# AT32M416xx_v2 register map
Vendor: Keil; Series: AT32M416; File version: 1.0
CPU: CM4 r0p1, little endian, no MPU, FPU, 4 interrupt priority bits
Registers are 32-bit, read-write, reset 0x0 unless marked. A register's access mark holds for its fields unless they carry their own. Offsets are from the block's base; [hi:lo] are bit positions; {n}, {i} and the like mark numbered series.

## TMR3 — General purpose timer
Base 0x40000400
Same registers: TMR4 0x40000800
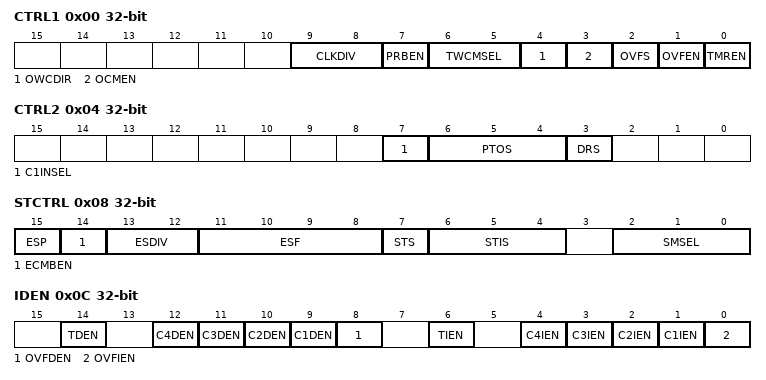
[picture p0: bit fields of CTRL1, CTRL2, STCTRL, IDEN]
0x00 CTRL1 — Control register 1
  [9:8] CLKDIV — Clock divider
  [7] PRBEN — Period buffer enable
  [6:5] TWCMSEL — Two-way count mode selection
  [4] OWCDIR — One-way count direction
  [3] OCMEN — One cycle mode enable
  [2] OVFS — Overflow event source
  [1] OVFEN — Overflow event enable
  [0] TMREN — TMR enable
0x04 CTRL2 — Control register 2
  [7] C1INSEL — C1IN selection
  [6:4] PTOS — Primary TMR output selection
  [3] DRS — DMA request source
0x08 STCTRL — Subordinate TMR control register
  [15] ESP — External signal polarity
  [14] ECMBEN — External clock mode B enable
  [13:12] ESDIV — External signal divider
  [11:8] ESF — External signal filter
  [7] STS — Subordinate TMR synchronization
  [6:4] STIS — Subordinate TMR input selection
  [2:0] SMSEL — Subordinate TMR mode selection
0x0C IDEN — Interrupt/DMA enable register
  [14] TDEN — Trigger DMA request enable
  [n+8] C{n}DEN (n=1..4) — Channel {n} DMA request enable
  [8] OVFDEN — Overflow DMA request enable
  [6] TIEN — Trigger interrupt enable
  [n] C{n}IEN (n=1..4) — Channel {n} interrupt enable
  [0] OVFIEN — Overflow interrupt enable
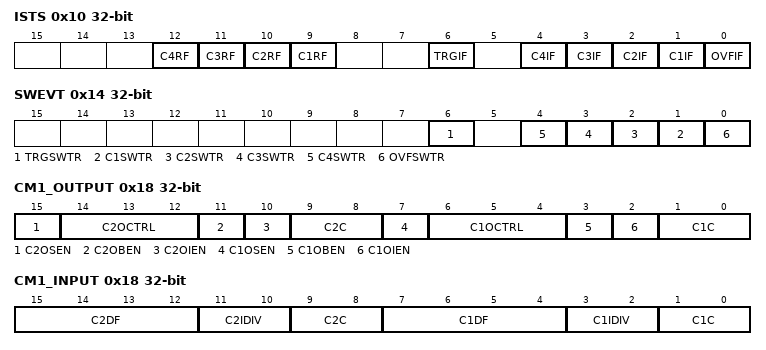
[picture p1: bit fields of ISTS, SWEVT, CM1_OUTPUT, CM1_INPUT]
0x10 ISTS — Interrupt status register
  [n+8] C{n}RF (n=1..4) — Channel {n} recapture flag
  [6] TRGIF — Trigger interrupt flag
  [n] C{n}IF (n=1..4) — Channel {n} interrupt flag
  [0] OVFIF — Overflow interrupt flag
0x14 SWEVT — Software event register
  [6] TRGSWTR — Trigger event triggered by software
  [n] C{n}SWTR (n=1..4) — Channel {n} event triggered by software
  [0] OVFSWTR — Overflow event triggered by software
0x18 CM1_OUTPUT — Channel output mode register
  [15] C2OSEN — Channel 2 output switch enable
  [14:12] C2OCTRL — Channel 2 output control
  [11] C2OBEN — Channel 2 output buffer enable
  [10] C2OIEN — Channel 2 output immediately enable
  [9:8] C2C — Channel 2 configure
  [7] C1OSEN — Channel 1 output switch enable
  [6:4] C1OCTRL — Channel 1 output control
  [3] C1OBEN — Channel 1 output buffer enable
  [2] C1OIEN — Channel 1 output immediately enable
  [1:0] C1C — Channel 1 configure
0x18 CM1_INPUT (alternate view of CM1_OUTPUT) — Channel input mode register 1
  [15:12] C2DF — Channel 2 digital filter
  [11:10] C2IDIV — Channel 2 input divider
  [9:8] C2C — Channel 2 configure
  [7:4] C1DF — Channel 1 digital filter
  [3:2] C1IDIV — Channel 1 input divider
  [1:0] C1C — Channel 1 configure
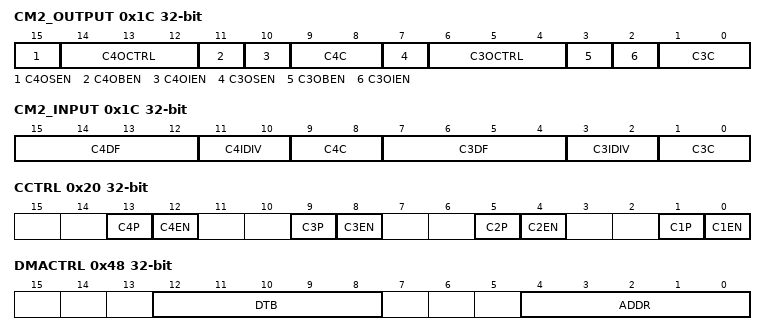
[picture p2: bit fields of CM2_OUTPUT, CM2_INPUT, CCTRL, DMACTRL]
0x1C CM2_OUTPUT — Channel output mode register 2
  [15] C4OSEN — Channel 4 output switch enable
  [14:12] C4OCTRL — Channel 4 output control
  [11] C4OBEN — Channel 4 output buffer enable
  [10] C4OIEN — Channel 4 output immediately enable
  [9:8] C4C — Channel 4 configure
  [7] C3OSEN — Channel 3 output switch enable
  [6:4] C3OCTRL — Channel 3 output control
  [3] C3OBEN — Channel 3 output buffer enable
  [2] C3OIEN — Channel 3 output immediately enable
  [1:0] C3C — Channel 3 configure
0x1C CM2_INPUT (alternate view of CM2_OUTPUT) — Channel input mode register 2
  [15:12] C4DF — Channel 4 digital filter
  [11:10] C4IDIV — Channel 4 input divider
  [9:8] C4C — Channel 4 configure
  [7:4] C3DF — Channel 3 digital filter
  [3:2] C3IDIV — Channel 3 input divider
  [1:0] C3C — Channel 3 configure
0x20 CCTRL — Channel control register
  [4n-3] C{n}P (n=1..4) — Channel {n} Polarity
  [4n-4] C{n}EN (n=1..4) — Channel {n} enable
0x24 CVAL — Counter value
  [15:0] CVAL
0x28 DIV — Divider value
  [15:0] DIV
0x2C PR — Period value
  [15:0] PR
{0x30+4i} C{i}DT (i=1..4) — Channel {i} data register
  [15:0] C{i}DT
0x48 DMACTRL — DMA control register
  [12:8] DTB — DMA transfer bytes
  [4:0] ADDR — DMA transfer address offset
0x4C DMADT — DMA data register
  [15:0] DMADT
0x50 OPT1 — option 1 register
  [0] CORAW_OFF — CORAW_OFF source selection
0x60 OPT2 — option 2 register
  [17:4] EXTSEL — EXT source selection
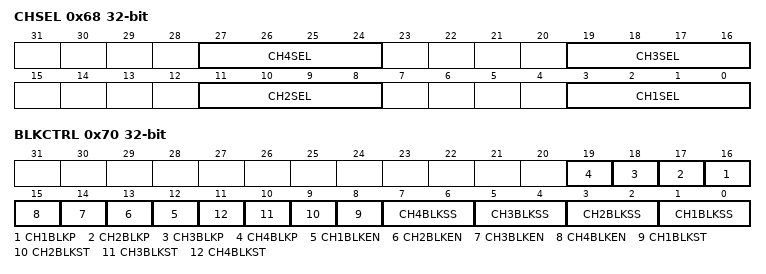
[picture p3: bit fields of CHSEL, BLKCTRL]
0x68 CHSEL — channel input selection register
  [8n-5:8n-8] CH{n}SEL (n=1..4) — CH{n} input selection
0x70 BLKCTRL — blanking control register
  [n+15] CH{n}BLKP (n=1..4) — CH{n} blanking polarity
  [n+11] CH{n}BLKEN (n=1..4) — CH{n} blanking enable
  [n+7] CH{n}BLKST (n=1..4) — CH{n} blanking state
  [2n-1:2n-2] CH{n}BLKSS (n=1..4) — CH{n} blanking sources selection
